# RZN2H register map
Vendor: Renesas Electronics Corporation; Series: RZN; File version: 1.00.00
CPU: other r0p0, little endian, MPU, no FPU, VTOR, 4 interrupt priority bits, 624 interrupts
Registers are 32-bit, read-write, reset 0x0 unless marked. A register's access mark holds for its fields unless they carry their own. Offsets are from the block's base; [hi:lo] are bit positions; 'fields as' and 'values as' point back to an identical list.

## CRC0 — CRC Unit 0
Base 0x80004000
Same registers: CRC1 0x81004000
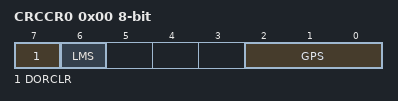
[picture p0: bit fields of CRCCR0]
0x00 CRCCR0 8-bit — CRC Control Register 0
  [7] DORCLR wo — CRCDOR Register Clear
    0=No effect; 1=Clears the CRCDOR register
  [6] LMS — CRC Calculation Switching
    0=Generates CRC for LSB first communication; 1=Generates CRC for MSB first communication
  [2:0] GPS — CRC Generating Polynomial Switching
    0=No calculation is executed; 1=8-bit CRC-8 (X8 + X2 + X + 1); 2=16-bit CRC-16 (X16 + X15 + X2 + 1); 3=16-bit CRC-CCITT (X16 + X12 + X5 + 1); 4=32-bit CRC-32 (X32 + X26 + X23 + X22 + X16 + X12 + X11 + X10 + X8 + X7 + X5 + X4 + X2 + X + 1); 5=32-bit CRC-32C (X32 + X28 + X27 + X26 + X25 + X23 + X22 + X20 + X19 + X18 + X14 + X13 + X11 + X10 + X9 + X8 + X6 + 1); other=Others (No calculation is executed.)
0x04 CRCDIR — CRC Data Input Register
0x04 CRCDIR_BY 8-bit (alternate view of CRCDIR) — CRC Data Input Register
0x08 CRCDOR — CRC Data Output Register
0x08 CRCDOR_HA 16-bit (alternate view of CRCDOR) — CRC Data Output Register
0x08 CRCDOR_BY 8-bit (alternate view of CRCDOR) — CRC Data Output Register

## CMTC — Compare Match Timer Control
Base 0x80080000
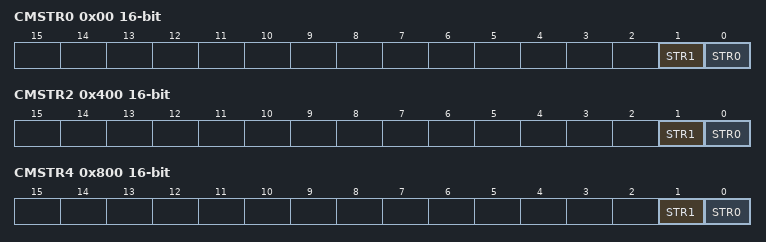
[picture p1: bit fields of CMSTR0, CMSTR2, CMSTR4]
0x00 CMSTR0 16-bit — Compare Match Timer Start Register
  [1] STR1 — CMT Channel n+1 Count Start
    0=The CMTn+1.CMCNT counter is stopped; 1=The CMTn+1.CMCNT counter is started
  [0] STR0 — CMT Channel n Count Start
    0=The CMTn.CMCNT counter is stopped; 1=The CMTn.CMCNT counter is started
0x400 CMSTR2 16-bit — Compare Match Timer Start Register
  fields as CMSTR0
0x800 CMSTR4 16-bit — Compare Match Timer Start Register
  fields as CMSTR0

## CMT0 — Compare Match Timer 0
Base 0x80080002
Same registers: CMT1 0x80080008, CMT2 0x80080402, CMT3 0x80080408, CMT4 0x80080802, CMT5 0x80080808
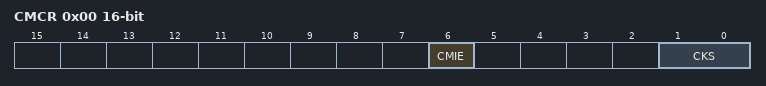
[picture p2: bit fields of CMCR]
0x00 CMCR 16-bit — Compare Match Timer Control Register
  [6] CMIE — Compare Match Interrupt Enable
    0=Compare match interrupt (CMTn_CMI) disabled; 1=Compare match interrupt (CMTn_CMI) enabled
  [1:0] CKS — Clock Select
    0=PCLKL/8; 1=PCLKL/32; 2=PCLKL/128; 3=PCLKL/512
0x02 CMCNT 16-bit — Compare Match Timer Counter Register
0x04 CMCOR 16-bit reset 0xFFFF — Compare Match Timer Constant Register

## WDT0 — Watchdog Timer 0
Base 0x80082000
Same registers: WDT1 0x80082400, WDT2 0x80082800, WDT3 0x80082C00, WDT4 0x80083000, WDT5 0x80083400
0x00 WDTRR 8-bit reset 0xFF — WDT Refresh Register
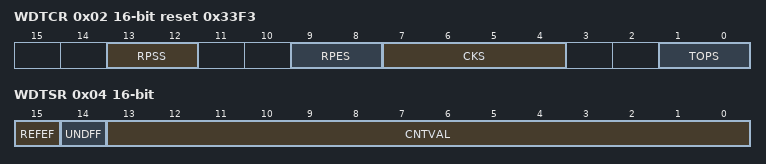
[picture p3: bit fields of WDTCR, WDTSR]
0x02 WDTCR 16-bit reset 0x33F3 — WDT Control Register
  [13:12] RPSS — Window Start Position Selection
    0=25%; 1=50%; 2=75%; 3=100% (window start position is not specified.)
  [9:8] RPES — Window End Position Selection
    0=75%; 1=50%; 2=25%; 3=0% (window end position is not specified.)
  [7:4] CKS — Clock Division Ratio Selection
    1=PCLKL/4; 4=PCLKL/64; 15=PCLKL/128; 6=PCLKL/512; 7=PCLKL/2048; 8=PCLKL/8192; other=Others (Setting prohibited.)
  [1:0] TOPS — Timeout Period Selection
    0=1024 cycles (0x03FF); 1=4096 cycles (0x0FFF); 2=8192 cycles (0x1FFF); 3=16384 cycles (0x3FFF)
0x04 WDTSR 16-bit — WDT Status Register
  [15] REFEF — Refresh Error Flag
    0=No refresh error occurred; 1=Refresh error occurred
  [14] UNDFF — Underflow Flag
    0=No underflow occurred; 1=Underflow occurred
  [13:0] CNTVAL ro — Down-Counter Value
0x06 WDTRCR 8-bit reset 0x80 — WDT Reset Control Register
  [7] RSTIRQS — Reset Interrupt Request Selection
    0=Error notification to ICU is permitted; 1=Error notification to ICU is not performed

## DOC — Data Operation Circuit
Base 0x80084000
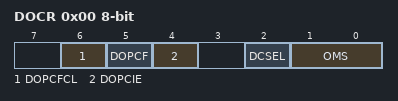
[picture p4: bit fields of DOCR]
0x00 DOCR 8-bit — DOC Control Register
  [6] DOPCFCL wo — DOPCF Flag Clear
    0=No effect; 1=Clear the DOPCF flag
  [5] DOPCF ro — Data Operation Circuit Flag
  [4] DOPCIE — Data Operation Circuit Interrupt Enable
    0=Disables interrupts from the data operation circuit; 1=Enables interrupts from the data operation circuit
  [2] DCSEL — Detection Condition Select
    0=Data mismatch is detected; 1=Data match is detected
  [1:0] OMS — Operating Mode Select
    0=Data comparison mode; 1=Data addition mode; 2=Data subtraction mode; 3=Setting prohibited
0x02 DODIR 16-bit — DOC Data Input Register
0x04 DODSR 16-bit — DOC Data Setting Register
